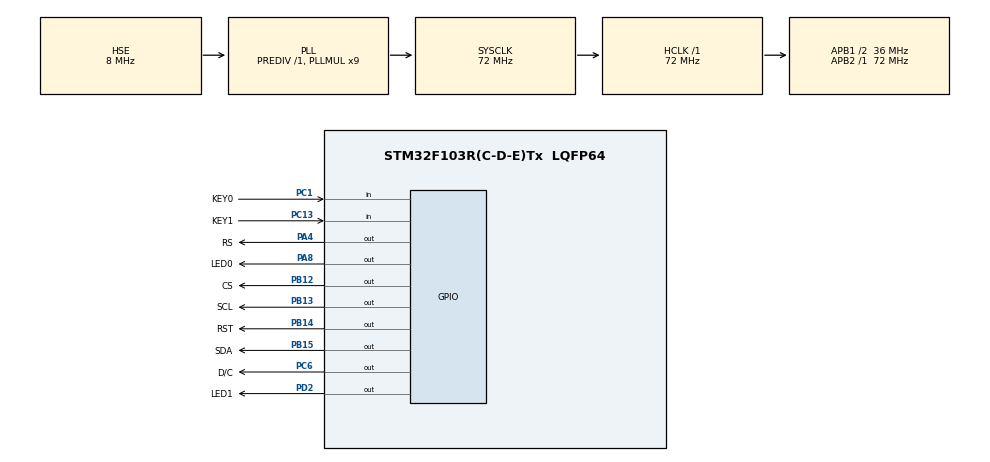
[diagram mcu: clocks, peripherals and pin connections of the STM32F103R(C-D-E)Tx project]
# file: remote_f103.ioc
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Mcu.Family=STM32F1
Mcu.Name=STM32F103R(C-D-E)Tx
Mcu.Package=LQFP64
NVIC.PriorityGroup=NVIC_PRIORITYGROUP_4
PA10.GPIO_Label=UART_RX
PA10.Signal=USART1_RX
PA13.Mode=Serial_Wire
PA13.Signal=SYS_JTMS-SWDIO
PA14.Mode=Serial_Wire
PA14.Signal=SYS_JTCK-SWCLK
PA4.GPIO_Label=RS
PA4.GPIO_ModeDefaultOutputPP=GPIO_MODE_OUTPUT_PP
PA4.GPIO_Speed=GPIO_SPEED_FREQ_MEDIUM
PA4.Signal=GPIO_Output
PA8.GPIO_Label=LED0
PA8.GPIO_PuPd=GPIO_PULLUP
PA8.GPIO_Speed=GPIO_SPEED_FREQ_LOW
PA8.PinState=GPIO_PIN_SET
PA8.Signal=GPIO_Output
PA9.GPIO_Label=UART1_TX
PA9.GPIO_Mode=GPIO_MODE_AF_PP
PA9.Signal=USART1_TX
PB12.GPIO_Label=CS
PB12.GPIO_ModeDefaultOutputPP=GPIO_MODE_OUTPUT_PP
PB12.GPIO_PuPd=GPIO_NOPULL
PB12.GPIO_Speed=GPIO_SPEED_FREQ_MEDIUM
PB12.PinState=GPIO_PIN_SET
PB12.Signal=GPIO_Output
PB13.GPIO_Label=SCL
PB13.GPIO_ModeDefaultOutputPP=GPIO_MODE_OUTPUT_PP
PB13.GPIO_Speed=GPIO_SPEED_FREQ_MEDIUM
PB13.PinState=GPIO_PIN_SET
PB13.Signal=GPIO_Output
PB14.GPIO_Label=RST
PB14.GPIO_Speed=GPIO_SPEED_FREQ_MEDIUM
PB14.PinState=GPIO_PIN_SET
PB14.Signal=GPIO_Output
PB15.GPIO_Label=SDA
PB15.GPIO_Speed=GPIO_SPEED_FREQ_MEDIUM
PB15.PinState=GPIO_PIN_SET
PB15.Signal=GPIO_Output
PC1.GPIO_Label=KEY0
PC1.GPIO_PuPd=GPIO_PULLUP
PC1.Signal=GPIO_Input
PC13-TAMPER-RTC.GPIO_Label=KEY1
PC13-TAMPER-RTC.GPIO_PuPd=GPIO_PULLUP
PC13-TAMPER-RTC.Signal=GPIO_Input
PC6.GPIO_Label=D/C
PC6.GPIO_Speed=GPIO_SPEED_FREQ_MEDIUM
PC6.PinState=GPIO_PIN_SET
PC6.Signal=GPIO_Output
PD0-OSC_IN.Mode=HSE-External-Oscillator
PD0-OSC_IN.Signal=RCC_OSC_IN
PD1-OSC_OUT.Mode=HSE-External-Oscillator
PD1-OSC_OUT.Signal=RCC_OSC_OUT
PD2.GPIO_Label=LED1
PD2.GPIO_PuPd=GPIO_PULLUP
PD2.PinState=GPIO_PIN_SET
PD2.Signal=GPIO_Output
ProjectManager.HeapSize=0x200
ProjectManager.StackSize=0x400
ProjectManager.TargetToolchain=MDK-ARM V5
RCC.ADCPresc=RCC_ADCPCLK2_DIV6
RCC.AHBFreq_Value=72000000
RCC.APB1CLKDivider=RCC_HCLK_DIV2
RCC.APB1Freq_Value=36000000
RCC.APB1TimFreq_Value=72000000
RCC.APB2Freq_Value=72000000
RCC.APB2TimFreq_Value=72000000
RCC.HCLKFreq_Value=72000000
RCC.PLLMUL=RCC_PLL_MUL9
RCC.PLLSourceVirtual=RCC_PLLSOURCE_HSE
RCC.SYSCLKFreq_VALUE=72000000
RCC.SYSCLKSource=RCC_SYSCLKSOURCE_PLLCLK
RCC.USBFreq_Value=72000000
board=custom

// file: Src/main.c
/* USER CODE BEGIN Header */
/**
  ******************************************************************************
  * @file           : main.c
  * @brief          : Main program body
  ******************************************************************************
  * @attention
  *
  * <h2><center>&copy; Copyright (c) 2020 STMicroelectronics.
  * All rights reserved.</center></h2>
  *
  * This software component is licensed by ST under BSD 3-Clause license,
  * the "License"; You may not use this file except in compliance with the
  * License. You may obtain a copy of the License at:
  *                        opensource.org/licenses/BSD-3-Clause
  *
  ******************************************************************************
  */
/* USER CODE END Header */

#include "main.h"
#include "gpio.h"

/* USER CODE BEGIN Includes */
#include "oled.h"
#include "bmp.h"
#include "stdio.h"
#include "string.h"
#include "os.h"

/* USER CODE END Includes */

void SystemClock_Config(void);

int main(void)
{

  /* MCU Configuration--------------------------------------------------------*/

  /* Reset of all peripherals, Initializes the Flash interface and the Systick. */
  HAL_Init();

  /* Configure the system clock */
  SystemClock_Config();

  /* USER CODE BEGIN SysInit */
	SysTick->CTRL  = 0x00;    			/* Important! Disable the systick and systick_handler */
  /* USER CODE END SysInit */

  /* Initialize all configured peripherals */
  MX_GPIO_Init();
  /* USER CODE BEGIN 2 */
	OLED_Init();			/*initialize OLED*/
	OLED_Clear();

	OSInit();

  OSStart();
  /* USER CODE END 2 */

  /* Infinite loop */
  while (1)
  {

  }
}

void SystemClock_Config(void)
{
  RCC_OscInitTypeDef RCC_OscInitStruct = {0};
  RCC_ClkInitTypeDef RCC_ClkInitStruct = {0};

  /** Initializes the CPU, AHB and APB busses clocks
  */
  RCC_OscInitStruct.OscillatorType = RCC_OSCILLATORTYPE_HSE;
  RCC_OscInitStruct.HSEState = RCC_HSE_ON;
  RCC_OscInitStruct.HSEPredivValue = RCC_HSE_PREDIV_DIV1;
  RCC_OscInitStruct.HSIState = RCC_HSI_ON;
  RCC_OscInitStruct.PLL.PLLState = RCC_PLL_ON;
  RCC_OscInitStruct.PLL.PLLSource = RCC_PLLSOURCE_HSE;
  RCC_OscInitStruct.PLL.PLLMUL = RCC_PLL_MUL9;
  if (HAL_RCC_OscConfig(&RCC_OscInitStruct) != HAL_OK)
  {
    Error_Handler();
  }
  /** Initializes the CPU, AHB and APB busses clocks
  */
  RCC_ClkInitStruct.ClockType = RCC_CLOCKTYPE_HCLK|RCC_CLOCKTYPE_SYSCLK
                              |RCC_CLOCKTYPE_PCLK1|RCC_CLOCKTYPE_PCLK2;
  RCC_ClkInitStruct.SYSCLKSource = RCC_SYSCLKSOURCE_PLLCLK;
  RCC_ClkInitStruct.AHBCLKDivider = RCC_SYSCLK_DIV1;
  RCC_ClkInitStruct.APB1CLKDivider = RCC_HCLK_DIV2;
  RCC_ClkInitStruct.APB2CLKDivider = RCC_HCLK_DIV1;

  if (HAL_RCC_ClockConfig(&RCC_ClkInitStruct, FLASH_LATENCY_2) != HAL_OK)
  {
    Error_Handler();
  }
}

void Error_Handler(void)
{
}

/************************ (C) COPYRIGHT STMicroelectronics *****END OF FILE****/
